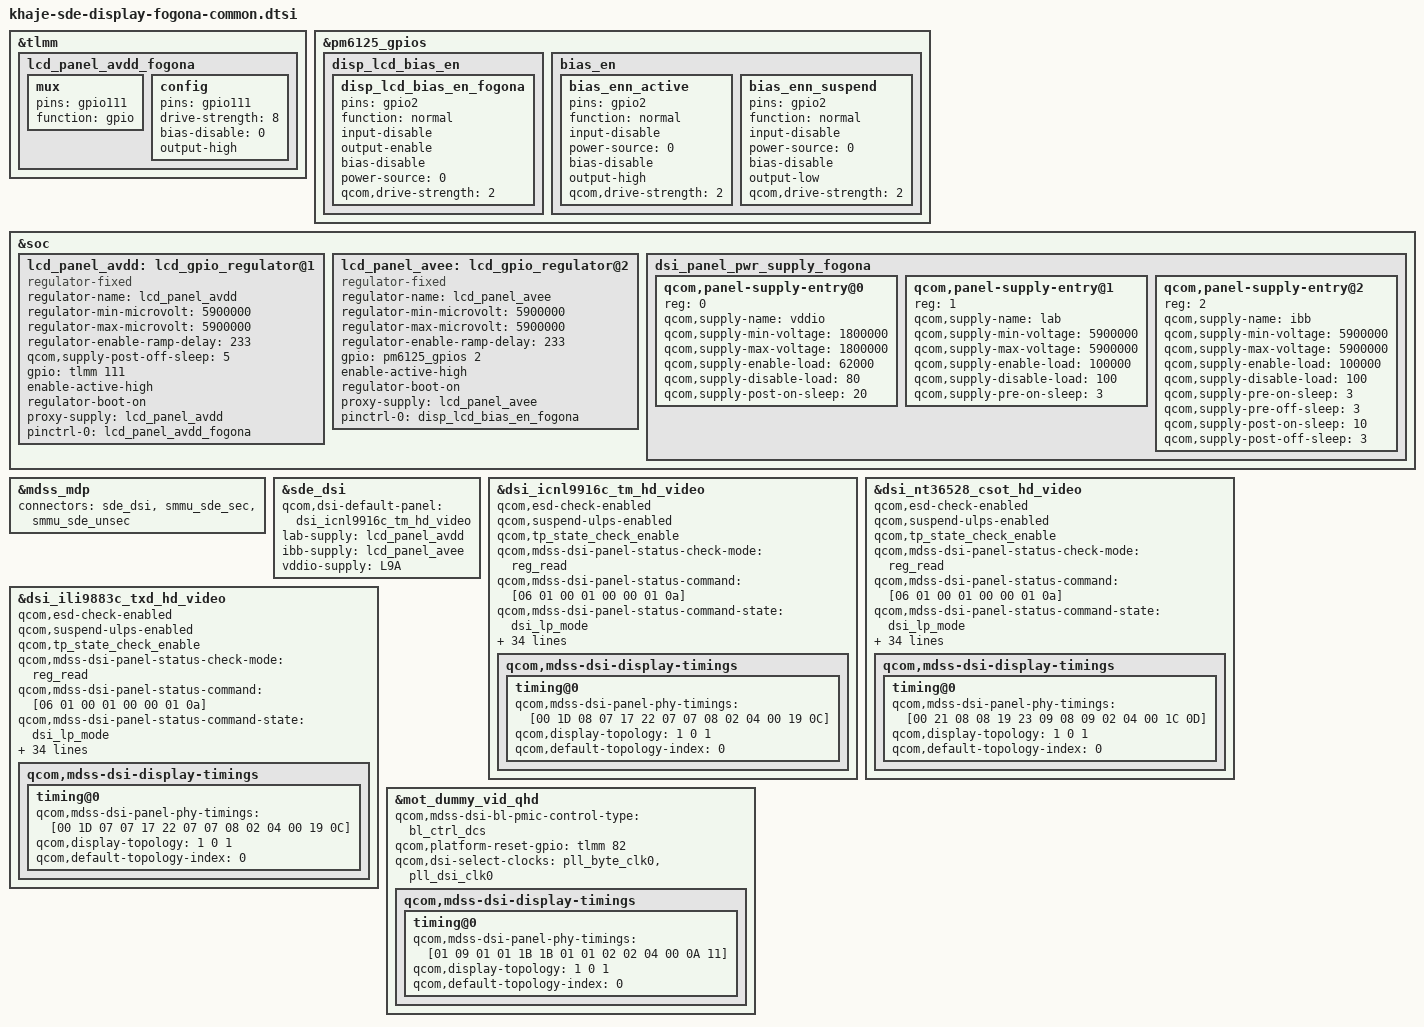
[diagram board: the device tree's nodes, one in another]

/* this is original from kalama-sde-display-mtp.dtsi */

#include "khaje-sde-display.dtsi"
#include "dsi-panel-mot-tm-icnl9916c-652-720x1600-vid.dtsi"
#include "dsi-panel-mot-csot-nt36528-652-720x1600-vid.dtsi"
#include "dsi-panel-mot-txd-ili9883c-652-720x1600-vid.dtsi"
#include "dsi-panel-mot-dummy-qhd-video.dtsi"

&tlmm {
        lcd_panel_avdd_fogona: lcd_panel_avdd_fogona {
                mux {
                        pins = "gpio111";
                        function = "gpio";
                };

                config {
                        pins = "gpio111";
                        drive-strength = <8>;
                        bias-disable = <0>;
                        output-high;
                };
        };
};

&pm6125_gpios {
        disp_lcd_bias_en {
                disp_lcd_bias_en_fogona: disp_lcd_bias_en_fogona {
                        pins = "gpio2";
                        function = "normal";
                        input-disable;
                        output-enable;
                        bias-disable;
                        power-source = <0>;
                        qcom,drive-strength = <2>;
                };
        };
        bias_en {
                bias_enn_active:bias_enn_active {
                        pins = "gpio2";
                        function = "normal";
                        input-disable;
                        power-source = <0>;
                        bias-disable;
                        output-high;
                        qcom,drive-strength = <2>;
                };
                bias_enn_suspend:bias_enn_suspend {
                        pins = "gpio2";
                        function = "normal";
                        input-disable;
                        power-source = <0>;
                        bias-disable;
                        output-low;
                        qcom,drive-strength = <2>;
                };
        };
};

&soc {
	lcd_panel_avdd: lcd_gpio_regulator@1 {
                compatible = "regulator-fixed";
                regulator-name = "lcd_panel_avdd";
                regulator-min-microvolt = <5900000>;
                regulator-max-microvolt = <5900000>;
                regulator-enable-ramp-delay = <233>;
                qcom,supply-post-off-sleep = <5>;
                gpio = <&tlmm 111 0>;
                enable-active-high;
                regulator-boot-on;
                proxy-supply = <&lcd_panel_avdd>;
                pinctrl-names = "fogona";
                pinctrl-0 = <&lcd_panel_avdd_fogona>;
        };

        lcd_panel_avee: lcd_gpio_regulator@2 {
                compatible = "regulator-fixed";
                regulator-name = "lcd_panel_avee";
                regulator-min-microvolt = <5900000>;
                regulator-max-microvolt = <5900000>;
                regulator-enable-ramp-delay = <233>;
                gpio = <&pm6125_gpios 2 0>;
                enable-active-high;
                regulator-boot-on;
                proxy-supply = <&lcd_panel_avee>;
                pinctrl-names = "fogona";
                pinctrl-0 = <&disp_lcd_bias_en_fogona>;
        };

        dsi_panel_pwr_supply_fogona: dsi_panel_pwr_supply_fogona {
                #address-cells = <1>;
                #size-cells = <0>;

                qcom,panel-supply-entry@0 {
                        reg = <0>;
                        qcom,supply-name = "vddio";
                        qcom,supply-min-voltage = <1800000>;
                        qcom,supply-max-voltage = <1800000>;
                        qcom,supply-enable-load = <62000>;
                        qcom,supply-disable-load = <80>;
                        qcom,supply-post-on-sleep = <20>;
                };

		qcom,panel-supply-entry@1 {
                        reg = <1>;
                        qcom,supply-name = "lab";
                        qcom,supply-min-voltage = <5900000>;
                        qcom,supply-max-voltage = <5900000>;
                        qcom,supply-enable-load = <100000>;
                        qcom,supply-disable-load = <100>;
                        qcom,supply-pre-on-sleep = <3>;
                };

                qcom,panel-supply-entry@2 {
                        reg = <2>;
                        qcom,supply-name = "ibb";
                        qcom,supply-min-voltage = <5900000>;
                        qcom,supply-max-voltage = <5900000>;
                        qcom,supply-enable-load = <100000>;
                        qcom,supply-disable-load = <100>;
                        qcom,supply-pre-on-sleep = <3>;
                        qcom,supply-pre-off-sleep = <3>;
                        qcom,supply-post-on-sleep = <10>;
                        qcom,supply-post-off-sleep = <3>;
                };
        };
};


&mdss_mdp {
	connectors = <&sde_dsi &smmu_sde_sec &smmu_sde_unsec>;
};


&sde_dsi {
	qcom,dsi-default-panel = <&dsi_icnl9916c_tm_hd_video>;
	lab-supply = <&lcd_panel_avdd>;
        ibb-supply = <&lcd_panel_avee>;
        vddio-supply = <&L9A>;
};

&dsi_icnl9916c_tm_hd_video {
        qcom,esd-check-enabled;
        qcom,suspend-ulps-enabled;
        qcom,tp_state_check_enable;
        qcom,mdss-dsi-panel-status-check-mode = "reg_read";
        qcom,mdss-dsi-panel-status-command = [06 01 00 01 00 00 01 0a];
        qcom,mdss-dsi-panel-status-command-state = "dsi_lp_mode";
        qcom,mdss-dsi-panel-status-value = <0x9c>;
        qcom,mdss-dsi-panel-status-read-length = <1>;
        qcom,cellid-read-enabled;
        qcom,mdss-dsi-panel-cellid-read-length = <23>;
        qcom,mdss-dsi-panel-cellid-read-times = <1>;
        qcom,mdss-dsi-panel-cellid-command = [
		39 01 00 00 00 00 04 F0 99 16 0C
		06 01 00 01 00 00 01 91
		39 01 00 00 00 00 04 F0 00 00 00];

        qcom,panel-supply-entries = <&dsi_panel_pwr_supply_fogona>;
        qcom,mdss-dsi-no-panel-on-read-support;
        qcom,mdss-dsi-reset-force-pull-low;
        qcom,platform-reset-gpio-always-on;
        qcom,mdss-dsi-bl-pmic-control-type = "bl_ctrl_dcs";
        qcom,mdss-dsi-bl-min-level = <9>;
        qcom,mdss-dsi-bl-max-level = <1637>;
        qcom,mdss-brightness-max-level = <1637>;
        qcom,platform-reset-gpio = <&tlmm 82 0>;
        qcom,dsi-supported-dfps-list = <60 90>;
        qcom,mdss-dsi-pan-enable-dynamic-fps;
        qcom,mdss-dsi-pan-fps-update = "dfps_immediate_porch_mode_vfp";
        qcom,mdss-dsi-panel-hbm-is-51cmd;
        qcom,mdss-dsi-hbm-type = "lcd-dcs-only";
        qcom,mdss-dsi-hbm-on-command = [39 01 00 00 00 00 03 51 07 FF];
        qcom,mdss-dsi-hbm-on-command-state =  "dsi_lp_mode";
        qcom,mdss-dsi-hbm-off-command = [39 01 00 00 00 00 03 51 06 66];
        qcom,mdss-dsi-hbm-off-command-state =  "dsi_lp_mode";
        qcom,dsi-select-clocks = "pll_byte_clk0", "pll_dsi_clk0";
	qcom,mdss-dsi-display-timings {
                timing@0 {
                        qcom,mdss-dsi-panel-phy-timings = [00 1D 08 07 17 22 07
                                        07 08 02 04 00 19 0C];
                        qcom,display-topology = <1 0 1>;
                        qcom,default-topology-index = <0>;
                };
        };
};

&dsi_nt36528_csot_hd_video {
        qcom,esd-check-enabled;
        qcom,suspend-ulps-enabled;
        qcom,tp_state_check_enable;
        qcom,mdss-dsi-panel-status-check-mode = "reg_read";
        qcom,mdss-dsi-panel-status-command = [06 01 00 01 00 00 01 0a];
        qcom,mdss-dsi-panel-status-command-state = "dsi_lp_mode";
        qcom,mdss-dsi-panel-status-value = <0x9c>;
        qcom,mdss-dsi-panel-status-read-length = <1>;
        qcom,cellid-read-enabled;
        qcom,mdss-dsi-panel-cellid-read-length = <1>;
        qcom,mdss-dsi-panel-cellid-read-times = <23>;
        qcom,mdss-dsi-panel-cellid-command = [
		39 01 00 00 00 00 02 FF 22
		39 01 00 00 00 00 02 FB 01
		06 01 00 01 00 00 01 00
		39 01 00 00 00 00 02 FF 10
		39 01 00 00 00 00 02 FB 01];

        qcom,panel-supply-entries = <&dsi_panel_pwr_supply_fogona>;
        qcom,mdss-dsi-no-panel-on-read-support;
        qcom,mdss-dsi-reset-force-pull-low;
        qcom,platform-reset-gpio-always-on;
        qcom,mdss-dsi-bl-pmic-control-type = "bl_ctrl_dcs";
        qcom,mdss-dsi-bl-min-level = <9>;
        qcom,mdss-dsi-bl-max-level = <1637>;
        qcom,mdss-brightness-max-level = <1637>;
        qcom,platform-reset-gpio = <&tlmm 82 0>;
        qcom,dsi-supported-dfps-list = <60 90>;
        qcom,mdss-dsi-pan-enable-dynamic-fps;
        qcom,mdss-dsi-pan-fps-update = "dfps_immediate_porch_mode_vfp";
        qcom,mdss-dsi-panel-hbm-is-51cmd;
        qcom,mdss-dsi-hbm-type = "lcd-dcs-only";
        qcom,mdss-dsi-hbm-on-command = [39 01 00 00 00 00 03 51 07 FF];
        qcom,mdss-dsi-hbm-on-command-state =  "dsi_lp_mode";
        qcom,mdss-dsi-hbm-off-command = [39 01 00 00 00 00 03 51 06 66];
        qcom,mdss-dsi-hbm-off-command-state =  "dsi_lp_mode";
        qcom,dsi-select-clocks = "pll_byte_clk0", "pll_dsi_clk0";
        qcom,mdss-dsi-display-timings {
                timing@0 {
                        qcom,mdss-dsi-panel-phy-timings = [00 21 08 08 19 23 09
                                        08 09 02 04 00 1C 0D];
                        qcom,display-topology = <1 0 1>;
                        qcom,default-topology-index = <0>;
                };
        };
};

&dsi_ili9883c_txd_hd_video {
        qcom,esd-check-enabled;
        qcom,suspend-ulps-enabled;
        qcom,tp_state_check_enable;
        qcom,mdss-dsi-panel-status-check-mode = "reg_read";
        qcom,mdss-dsi-panel-status-command = [06 01 00 01 00 00 01 0a];
        qcom,mdss-dsi-panel-status-command-state = "dsi_lp_mode";
        qcom,mdss-dsi-panel-status-value = <0x9c>;
        qcom,mdss-dsi-panel-status-read-length = <1>;
        qcom,cellid-read-enabled;
        qcom,mdss-dsi-panel-cellid-read-length = <1>;
        qcom,mdss-dsi-panel-cellid-read-times = <23>;
        qcom,mdss-dsi-panel-cellid-command = [
                39 01 00 00 00 00 04 FF 98 83 0B
                06 01 00 01 00 00 01 00
                39 01 00 00 00 00 04 FF 98 83 00];

        qcom,panel-supply-entries = <&dsi_panel_pwr_supply_fogona>;
        qcom,mdss-dsi-no-panel-on-read-support;
        qcom,mdss-dsi-reset-force-pull-low;
        qcom,platform-reset-gpio-always-on;
        qcom,mdss-dsi-bl-pmic-control-type = "bl_ctrl_dcs";
        qcom,mdss-dsi-bl-min-level = <9>;
        qcom,mdss-dsi-bl-max-level = <1637>;
        qcom,mdss-brightness-max-level = <1637>;
        qcom,platform-reset-gpio = <&tlmm 82 0>;
        qcom,dsi-supported-dfps-list = <60 90>;
        qcom,mdss-dsi-pan-enable-dynamic-fps;
        qcom,mdss-dsi-pan-fps-update = "dfps_immediate_porch_mode_vfp";
        qcom,mdss-dsi-panel-hbm-is-51cmd;
        qcom,mdss-dsi-hbm-type = "lcd-dcs-only";
        qcom,mdss-dsi-hbm-on-command = [39 01 00 00 00 00 03 51 07 FF];
        qcom,mdss-dsi-hbm-on-command-state =  "dsi_lp_mode";
        qcom,mdss-dsi-hbm-off-command = [39 01 00 00 00 00 03 51 06 66];
        qcom,mdss-dsi-hbm-off-command-state =  "dsi_lp_mode";
        qcom,dsi-select-clocks = "pll_byte_clk0", "pll_dsi_clk0";
        qcom,mdss-dsi-display-timings {
                timing@0 {
                        qcom,mdss-dsi-panel-phy-timings = [00 1D 07 07 17 22 07
                                        07 08 02 04 00 19 0C];
                        qcom,display-topology = <1 0 1>;
                        qcom,default-topology-index = <0>;
                };
        };

};

&mot_dummy_vid_qhd {
	qcom,mdss-dsi-bl-pmic-control-type = "bl_ctrl_dcs";
	qcom,platform-reset-gpio = <&tlmm 82 0>;
	qcom,dsi-select-clocks = "pll_byte_clk0", "pll_dsi_clk0";
    qcom,mdss-dsi-display-timings {
        timing@0 {
            qcom,mdss-dsi-panel-phy-timings = [01 09 01 01 1B 1B 01
                    01 02 02 04 00 0A 11];
            qcom,display-topology = <1 0 1>;
            qcom,default-topology-index = <0>;
        };
    };
};

